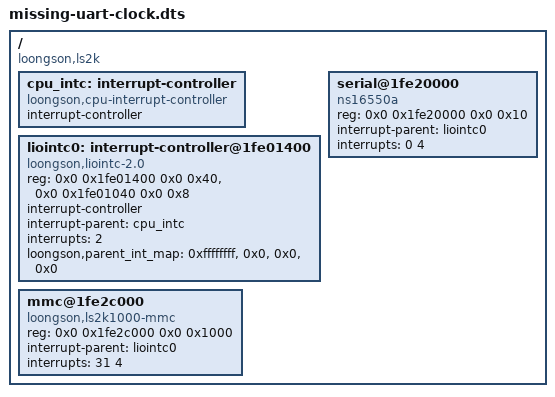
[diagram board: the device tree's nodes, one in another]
/dts-v1/;

/ {
    compatible = "loongson,ls2k";
    #address-cells = <2>;
    #size-cells = <2>;

    cpu_intc: interrupt-controller {
        compatible = "loongson,cpu-interrupt-controller";
        interrupt-controller;
        #interrupt-cells = <1>;
    };

    liointc0: interrupt-controller@1fe01400 {
        compatible = "loongson,liointc-2.0";
        reg = <0x0 0x1fe01400 0x0 0x40>,
              <0x0 0x1fe01040 0x0 0x8>;
        reg-names = "main", "isr0";
        interrupt-controller;
        #interrupt-cells = <2>;
        interrupt-parent = <&cpu_intc>;
        interrupts = <2>;
        interrupt-names = "int0";
        loongson,parent_int_map = <0xffffffff>, <0x0>, <0x0>, <0x0>;
    };

    serial@1fe20000 {
        compatible = "ns16550a";
        reg = <0x0 0x1fe20000 0x0 0x10>;
        interrupt-parent = <&liointc0>;
        interrupts = <0 4>;
    };

    mmc@1fe2c000 {
        compatible = "loongson,ls2k1000-mmc";
        reg = <0x0 0x1fe2c000 0x0 0x1000>;
        interrupt-parent = <&liointc0>;
        interrupts = <31 4>;
    };
};
